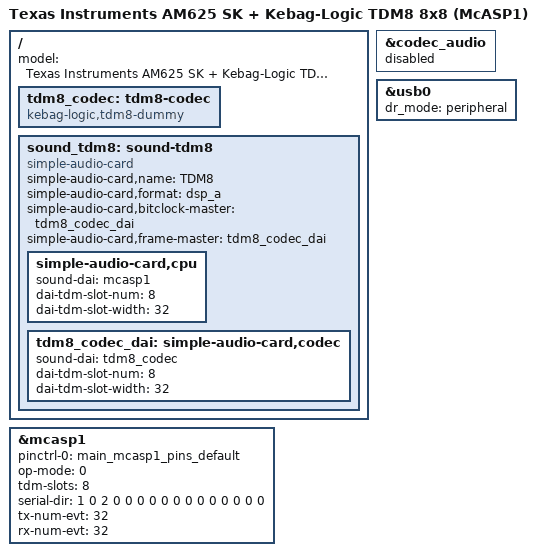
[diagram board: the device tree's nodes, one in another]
// SPDX-License-Identifier: GPL-2.0-only OR MIT
/*
 * TDM8 (8 in / 8 out) on McASP1 for the TI SK-AM62B-P1, bridged to the USB
 * Audio Class 2.0 gadget on the USB-C port.
 *
 * SPDX-FileCopyrightText: Copyright (c) 2026 Kebag-Logic
 *
 * Built in-tree: res/tdm8-sk/apply-tdm8-sk-dts.sh drops this next to
 * k3-am625-sk.dts and registers it in ti/Makefile, so
 *   make ARCH=arm64 ti/k3-am625-sk-tdm8.dtb
 * produces it.  Unlike the MYIR board there is no vendor blob to inject into -
 * mainline carries the SK device tree, so this is ordinary source.
 *
 * Pads - identical to the MYIR MYD-YM62X TDM8 link, because TI's own
 * main_mcasp1_pins_default already muxes exactly these four the right way
 * round (see k3-am62x-sk-common.dtsi):
 *
 *   pad 0x0090 mux2  MCASP1_ACLKX  ball M24  <- FPGA BCLK  12.288 MHz
 *   pad 0x0098 mux2  MCASP1_AFSX   ball U23  <- FPGA FSYNC 48 kHz
 *   pad 0x008c mux2  MCASP1_AXR0   ball L25  -> FPGA DIN   (8 slots out)
 *   pad 0x0084 mux2  MCASP1_AXR2   ball L23  <- FPGA DOUT  (8 slots in)
 *
 * On the SK those four nets are the on-board audio bus: they reach the
 * TLV320AIC3106 codec, the SII9022 HDMI bridge and the M.2 E-key BT PCM pins
 * through the FET switch / buffer steered by the TCA6424 expander.  Only AXR2
 * (J3-15) and AXR1 (J3-31) come out on the 40-pin header, so the FPGA cable
 * taps the bus at the M.2 E-key connector or at the buffer - see
 * README.tdm8-sk-am62b.md for the connector table and the FET lines.
 */

#include "k3-am625-sk.dts"

/ {
	model = "Texas Instruments AM625 SK + Kebag-Logic TDM8 8x8 (McASP1)";

	tdm8_codec: tdm8-codec {
		compatible = "kebag-logic,tdm8-dummy";
		#sound-dai-cells = <0>;
		status = "okay";
	};

	sound_tdm8: sound-tdm8 {
		compatible = "simple-audio-card";
		simple-audio-card,name = "TDM8";
		/*
		 * dsp_a: 1-BCLK-wide frame sync, slot 0 starts one BCLK after
		 * the FSYNC edge, MSB first.  Switch to "dsp_b" if the FPGA
		 * emits slot 0 on the FSYNC edge itself; add
		 * simple-audio-card,frame-inversion if FSYNC is active low.
		 */
		simple-audio-card,format = "dsp_a";
		/*
		 * Both phandles point at the codec DAI => the FPGA is bit-clock
		 * and frame master.  ASoC reads these "from the codec
		 * perspective" (CBP_CFP) and flips them for the CPU DAI, so
		 * davinci-mcasp gets BC_FC, clears ACLKXE/AFSXE and leaves
		 * ACLKX/AFSX as inputs - matching PIN_INPUT in TI's
		 * main_mcasp1_pins_default.  Point them at the cpu subnode
		 * instead and McASP drives the clocks.
		 */
		simple-audio-card,bitclock-master = <&tdm8_codec_dai>;
		simple-audio-card,frame-master = <&tdm8_codec_dai>;

		simple-audio-card,cpu {
			sound-dai = <&mcasp1>;
			dai-tdm-slot-num = <8>;
			dai-tdm-slot-width = <32>;
		};

		tdm8_codec_dai: simple-audio-card,codec {
			sound-dai = <&tdm8_codec>;
			dai-tdm-slot-num = <8>;
			dai-tdm-slot-width = <32>;
		};
	};
};

/* mcasp1 belongs to exactly one card; the 2-channel on-board one steps aside */
&codec_audio {
	status = "disabled";
};

&mcasp1 {
	/* TI's group already has ACLKX/AFSX/AXR2 in and AXR0 out at mux 2 */
	pinctrl-names = "default";
	pinctrl-0 = <&main_mcasp1_pins_default>;

	op-mode = <0>;			/* DAVINCI_MCASP_IIS_MODE (not DIT) */
	tdm-slots = <8>;

	/*
	 * One serializer per direction is all a TDM8 link needs:
	 * 0 = inactive, 1 = TX, 2 = RX.  AXR0 transmits the 8 output slots,
	 * AXR2 receives the 8 input slots.
	 */
	serial-dir = <
		1 0 2 0
		0 0 0 0
		0 0 0 0
		0 0 0 0
	>;
	tx-num-evt = <32>;
	rx-num-evt = <32>;
	/*
	 * No "ti,async-mode": MCASP1_ACLKR/AFSR are not wired on this board, so
	 * receive stays in the transmit clock domain.  Synchronous mode also
	 * forces both directions to the same rate and framing, which is what
	 * the alsaloop bridge wants anyway.
	 */
	status = "okay";
};

/*
 * The UAC2 gadget wants the Type-C port in device role deterministically.
 * Power delivery is negotiated by the TPS6598x independently of this, so
 * forcing peripheral does not affect how the board is powered.  Drop this
 * override to go back to mainline's PD-controller role switching.
 */
&usb0 {
	dr_mode = "peripheral";
};

/*
 * Isolating the on-board loads from the McASP1 bus.
 *
 * exp1 (TCA6424 @ 0x22 on main_i2c1) owns three lines that steer this bus,
 * named in mainline as:
 *
 *   line 18  MCASP1_FET_EN
 *   line 19  MCASP1_BUF_BT_EN
 *   line 20  MCASP1_FET_SEL
 *
 * The polarity is NOT documented in the device tree, so this BSP does not hog
 * them - a wrong guess would drive the codec and the FPGA into each other.
 * Find the right states with gpioset first (README.tdm8-sk-am62b.md), then
 * uncomment and fix the levels here to make them survive a reboot:
 *
 *	&exp1 {
 *		mcasp1-fet-en-hog {
 *			gpio-hog;
 *			gpios = <18 GPIO_ACTIVE_HIGH>;
 *			output-low;
 *			line-name = "MCASP1_FET_EN";
 *		};
 *
 *		mcasp1-buf-bt-en-hog {
 *			gpio-hog;
 *			gpios = <19 GPIO_ACTIVE_HIGH>;
 *			output-low;
 *			line-name = "MCASP1_BUF_BT_EN";
 *		};
 *	};
 */
